VERSION ""

NS_ :

BS_:

BU_: XXX

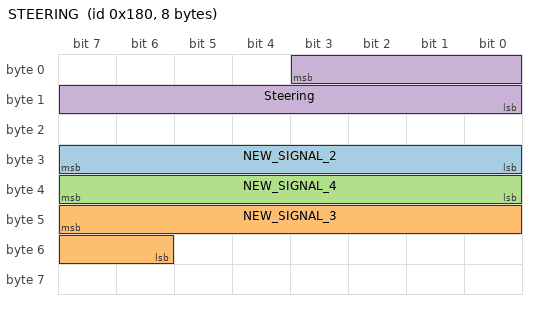
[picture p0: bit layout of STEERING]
BO_ 384 STEERING: 8 XXX
 SG_ NEW_SIGNAL_2 : 31|8@0- (1,0) [0|255] "" XXX
 SG_ NEW_SIGNAL_3 : 47|10@0- (1,0) [0|1023] "" XXX
 SG_ NEW_SIGNAL_4 : 39|8@0- (1,0) [0|255] "" XXX
 SG_ Steering : 3|12@0- (1,0) [0|4095] "" XXX
